# EFM32G210 register map
File version: 2.7.3
CPU: CM3 r2p0, little endian, MPU, no FPU, 3 interrupt priority bits
Registers are 32-bit, read-write, reset 0x0 unless marked. A register's access mark holds for its fields unless they carry their own. Offsets are from the block's base; [hi:lo] are bit positions.

## MSC
Base 0x400C0000
0x00 CTRL reset 0x1 — Memory System Control Register
  [0] BUSFAULT — Bus Fault Response Enable
0x04 READCTRL reset 0x1 — Read Control Register
  [2:0] MODE — Read Mode
    0=WS0 (Zero wait-states inserted in fetch or read transfers.); 1=WS1 (One wait-state inserted for each fetch or read transfer. This mode is required for a core frequency above 16 MHz.); 2=WS0SCBTP (Zero wait-states inserted with the Suppressed Conditional Branch Target Prefetch (SCBTP) function enabled. SCBTP saves energy by delaying the Cortex' conditional branch target prefetches until the conditional branch instruction is in the execute stage. When the instruction reaches this stage, the evaluation of the branch condition is completed and the core does not perform a speculative prefetch of both the branch target address and the next sequential address. With the SCBTP function enabled, one instruction fetch is saved for each branch not taken, with a negligible performance penalty.); 3=WS1SCBTP (One wait-state access with SCBTP enabled.)
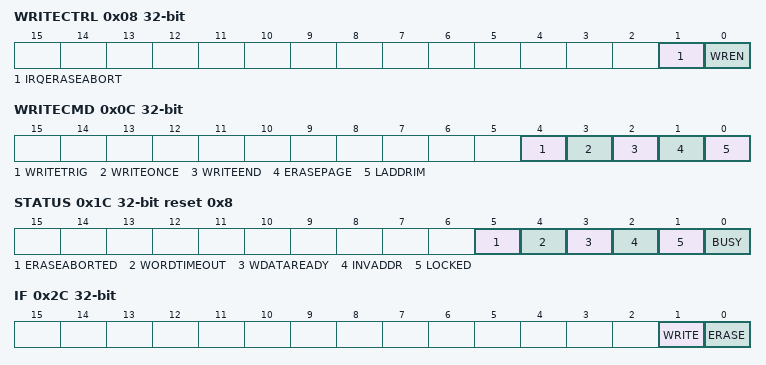
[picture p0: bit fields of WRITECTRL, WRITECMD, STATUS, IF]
0x08 WRITECTRL — Write Control Register
  [1] IRQERASEABORT — Abort Page Erase on Interrupt
  [0] WREN — Enable Write/Erase Controller
0x0C WRITECMD wo — Write Command Register
  [4] WRITETRIG — Word Write Sequence Trigger
  [3] WRITEONCE — Word Write-Once Trigger
  [2] WRITEEND — End Write Mode
  [1] ERASEPAGE
  [0] LADDRIM — Load MSC_ADDRB into ADDR
0x10 ADDRB — Page Erase/Write Address Buffer
  [31:0] ADDRB — Page Erase or Write Address Buffer
0x18 WDATA — Write Data Register
  [31:0] WDATA — Write Data
0x1C STATUS ro reset 0x8
  [5] ERASEABORTED — The Current Flash Erase Operation Aborted
  [4] WORDTIMEOUT — Flash Write Word Timeout
  [3] WDATAREADY — WDATA Write Ready
  [2] INVADDR — Invalid Write Address or Erase Page
  [1] LOCKED — Access Locked
  [0] BUSY — Erase/Write Busy
0x2C IF ro — Interrupt Flag Register
  [1] WRITE — Write Done Interrupt Read Flag
  [0] ERASE — Erase Done Interrupt Read Flag
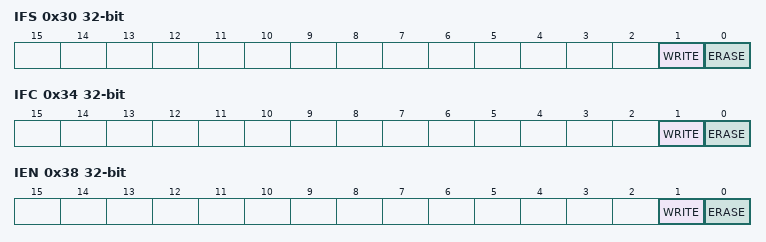
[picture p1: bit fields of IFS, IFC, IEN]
0x30 IFS wo — Interrupt Flag Set Register
  [1] WRITE — Write Done Interrupt Set
  [0] ERASE — Erase Done Interrupt Set
0x34 IFC wo — Interrupt Flag Clear Register
  [1] WRITE — Write Done Interrupt Clear
  [0] ERASE — Erase Done Interrupt Clear
0x38 IEN — Interrupt Enable Register
  [1] WRITE — Write Done Interrupt Enable
  [0] ERASE — Erase Done Interrupt Enable
0x3C LOCK — Configuration Lock Register
  [15:0] LOCKKEY — Configuration Lock
    0=UNLOCKED; 1=LOCKED

## EMU
Base 0x400C6000
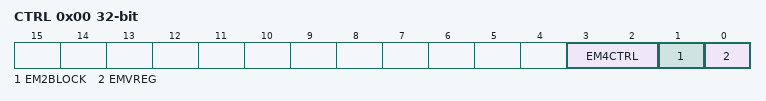
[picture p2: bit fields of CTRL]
0x00 CTRL — Control Register
  [3:2] EM4CTRL — Energy Mode 4 Control
  [1] EM2BLOCK — Energy Mode 2 Block
  [0] EMVREG — Energy Mode Voltage Regulator Control
0x04 MEMCTRL — Memory Control Register
  [2:0] POWERDOWN — RAM block power-down
    4=BLK3 (Power down RAM block 3 (address range 0x20018000-0x2001FFFF).); 6=BLK23 (Power down RAM blocks 2-3 (address range 0x20010000-0x2001FFFF).); 7=BLK123 (Power down RAM blocks 1-3 (address range 0x20008000-0x2001FFFF).)
0x08 LOCK — Configuration Lock Register
  [15:0] LOCKKEY — Configuration Lock Key
    0=UNLOCKED; 1=LOCKED
0x24 AUXCTRL — Auxiliary Control Register
  [0] HRCCLR — Hard Reset Cause Clear

## RMU
Base 0x400CA000
0x00 CTRL — Control Register
  [0] LOCKUPRDIS — Lockup Reset Disable
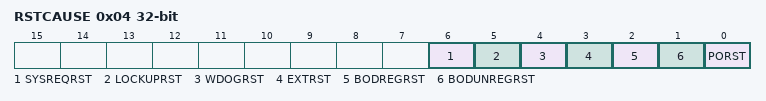
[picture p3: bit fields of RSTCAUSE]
0x04 RSTCAUSE ro — Reset Cause Register
  [6] SYSREQRST — System Request Reset
  [5] LOCKUPRST — LOCKUP Reset
  [4] WDOGRST — Watchdog Reset
  [3] EXTRST — External Pin Reset
  [2] BODREGRST — Brown Out Detector Regulated Domain Reset
  [1] BODUNREGRST — Brown Out Detector Unregulated Domain Reset
  [0] PORST — Power On Reset
0x08 CMD wo — Command Register
  [0] RCCLR — Reset Cause Clear

## RTC
Base 0x40080000
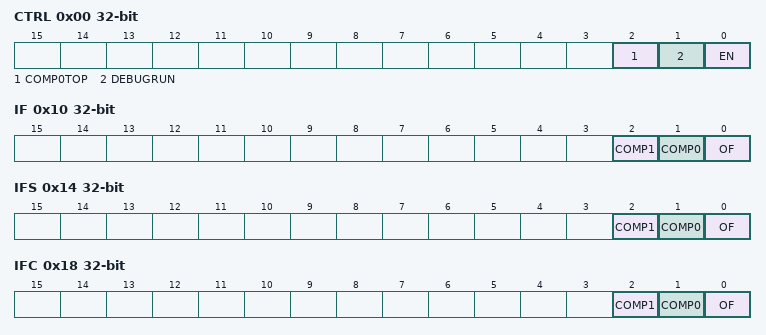
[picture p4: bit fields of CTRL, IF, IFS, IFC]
0x00 CTRL — Control Register
  [2] COMP0TOP — Compare Channel 0 is Top Value
  [1] DEBUGRUN — Debug Mode Run Enable
  [0] EN — RTC Enable
0x04 CNT ro — Counter Value Register
  [23:0] CNT — Counter Value
0x08 COMP0 — Compare Value Register 0
  [23:0] COMP0 — Compare Value 0
0x0C COMP1 — Compare Value Register 1
  [23:0] COMP1 — Compare Value 1
0x10 IF ro — Interrupt Flag Register
  [2] COMP1 — Compare Match 1 Interrupt Flag
  [1] COMP0 — Compare Match 0 Interrupt Flag
  [0] OF — Overflow Interrupt Flag
0x14 IFS wo — Interrupt Flag Set Register
  [2] COMP1 — Set Compare match 1 Interrupt Flag
  [1] COMP0 — Set Compare match 0 Interrupt Flag
  [0] OF — Set Overflow Interrupt Flag
0x18 IFC wo — Interrupt Flag Clear Register
  [2] COMP1 — Clear Compare match 1 Interrupt Flag
  [1] COMP0 — Clear Compare match 0 Interrupt Flag
  [0] OF — Clear Overflow Interrupt Flag
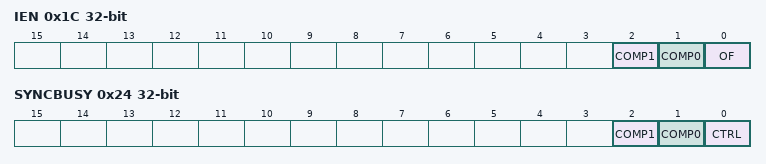
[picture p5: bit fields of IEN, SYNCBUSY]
0x1C IEN — Interrupt Enable Register
  [2] COMP1 — Compare Match 1 Interrupt Enable
  [1] COMP0 — Compare Match 0 Interrupt Enable
  [0] OF — Overflow Interrupt Enable
0x20 FREEZE
  [0] REGFREEZE — Register Update Freeze
0x24 SYNCBUSY ro — Synchronization Busy Register
  [2] COMP1 — COMP1 Register Busy
  [1] COMP0 — COMP0 Register Busy
  [0] CTRL — CTRL Register Busy

## Notices in the file
# License
Copyright 2020 Silicon Laboratories Inc. www.silabs.com
SPDX-License-Identifier: Zlib
The licensor of this software is Silicon Laboratories Inc.
This software is provided 'as-is', without any express or implied
warranty. In no event will the authors be held liable for any damages
arising from the use of this software.
Permission is granted to anyone to use this software for any purpose,
including commercial applications, and to alter it and redistribute it
freely, subject to the following restrictions:
1. The origin of this software must not be misrepresented; you must not
claim that you wrote the original software. If you use this software
in a product, an acknowledgment in the product documentation would be
appreciated but is not required.
2. Altered source versions must be plainly marked as such, and must not be
misrepresented as being the original software.
3. This notice may not be removed or altered from any source distribution.
